# ATSAMRH707F18A device description
Architecture: CORTEX-M7; Family: SAMRH; Series: SAMRH707
Registers are 32-bit, read-write, no defined reset value unless marked. A register's access mark holds for its fields unless they carry their own. Offsets are from the block's base; [hi:lo] are bit positions; {n}, {i} and the like mark numbered series.

## NMIC — Non-maskable Interrupt Controller
Instances: NMIC 0x400A8000
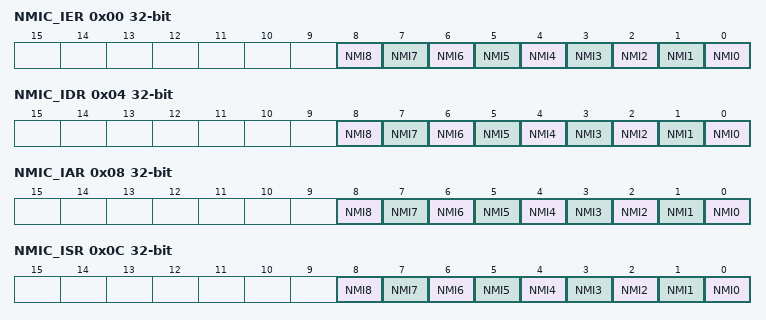
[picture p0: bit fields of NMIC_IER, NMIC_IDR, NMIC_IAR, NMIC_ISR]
0x00 NMIC_IER wo — Interrupt Enable Register
  [n] NMI{n} (n=0..8) — Non-maskable Interrupt {n} Enable
0x04 NMIC_IDR wo — Interrupt Disable Register
  [n] NMI{n} (n=0..8) — Non-maskable Interrupt {n} Disable
0x08 NMIC_IAR ro — Interrupt Active Register
  [n] NMI{n} (n=0..8) — Active Interrupt {n}
0x0C NMIC_ISR ro — Interrupt Status Register
  [n] NMI{n} (n=0..8) — Non-maskable Interrupt Source {n} Pending (cleared on read)
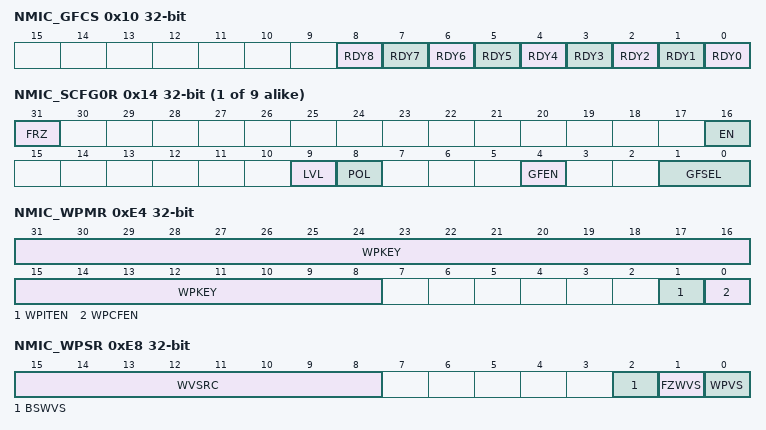
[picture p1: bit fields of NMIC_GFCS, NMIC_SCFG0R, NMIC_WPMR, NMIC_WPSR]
0x10 NMIC_GFCS ro — Glitch Filter Configuration Status Register
  [n] RDY{n} (n=0..8) — Filter {n} Configuration Ready
{0x14+4i} NMIC_SCFG{i}R (i=0..8) — Source Configuration Register {i}
  [31] FRZ — Interrupt Line Freeze
  [16] EN — Source Enable
  [9] LVL — Level Detection (LVL bit is read-only in NMIC_SCFG1 to 8)
  [8] POL — Polarity (POL bit is read-only in NMIC_SCFG1 to 8)
  [4] GFEN — Glitch Filter Enable (GFEN bit is read-only in NMIC_SCFG1 to 8)
  [1:0] GFSEL — Glitch Filter Selector (GFSEL field is read-only in NMIC_SCFG1 to 8)
0xE4 NMIC_WPMR — Write Protection Mode Register
  [31:8] WPKEY — Write Protection Key
    0x4E4D49=PASSWD (Writing any other value in this field aborts the write operation of the WPCFEN and WPITEN bit. Always reads as 0.)
  [1] WPITEN — Write Protection Interrupt Enable
  [0] WPCFEN — Write Protection Configuration Enable
0xE8 NMIC_WPSR ro — Write Protection Status Register
  [15:8] WVSRC — Write Violation Source
  [2] BSWVS — Busy Register Write Violation Status
  [1] FZWVS — Frozen Register Write Violation Status
  [0] WPVS — Write Protection Register Violation Status

## PCC — Parallel Capture Controller
Instances: PCC 0x4001C000
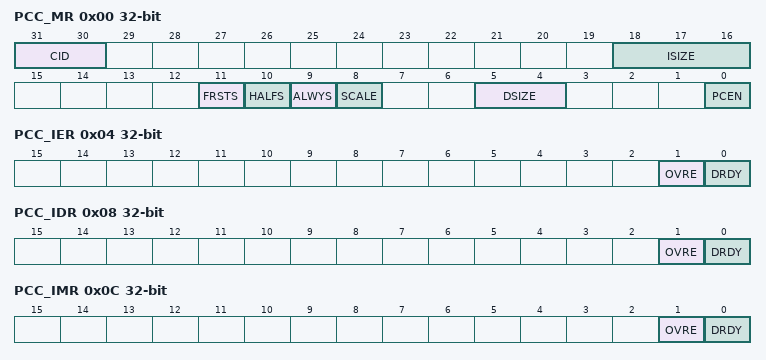
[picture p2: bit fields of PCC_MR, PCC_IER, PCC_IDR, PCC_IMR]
0x00 PCC_MR — Mode Register
  [31:30] CID — Clear If Disabled
    0=NONE (Clear not enabled); 1=DEN1 (Clear on falling edge on DEN1 enabled); 2=DEN2 (Clear on falling edge on DEN2 enabled); 3=EITHER (Clear on falling edge on either DEN1 or DEN2 enabled)
  [18:16] ISIZE — Input Data Size
    0=8_BITS (Input data bus size is 8 bits); 1=10_BITS (Input data bus size is 10 bits); 2=12_BITS (Input data bus size is 12 bits); 3=14_BITS (Input data bus size is 14 bits); 4=16_BITS (Input data bus size is 16 bits)
  [11] FRSTS — First Sample
  [10] HALFS — Half Sampling
  [9] ALWYS — Always Sampling
  [8] SCALE — Scale Data
  [5:4] DSIZE — Data Size
    0=1_DATA (1 data is read in the PCC_RHR); 1=2_DATA (2 data are read in the PCC_RHR); 2=4_DATA (4 data are read in the PCC_RHR (only for 8 bits data size, ISIZE = 0))
  [0] PCEN — Parallele Capture Enable
0x04 PCC_IER wo (atomic set of PCC_IMR) — Interrupt Enable Register
  [1] OVRE — Overrun Error Interrupt Enable
  [0] DRDY — Data Ready Interrupt Enable
0x08 PCC_IDR wo (atomic clear of PCC_IMR) — Interrupt Disable Register
  [1] OVRE — Overrun Error Interrupt Disable
  [0] DRDY — Data Ready Interrupt Disable
0x0C PCC_IMR ro — Interrupt Mask Register
  [1] OVRE — Overrun Error Interrupt Mask
  [0] DRDY — Data Ready Interrupt Mask
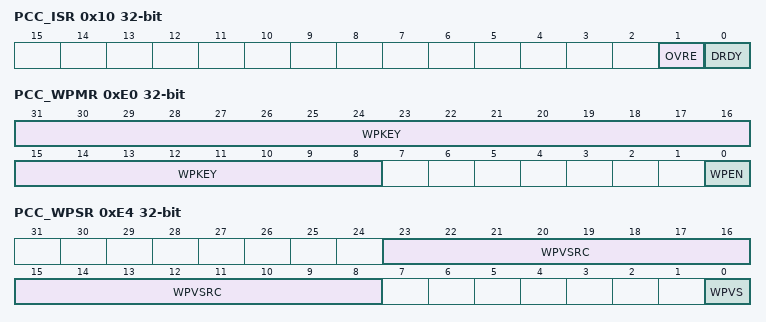
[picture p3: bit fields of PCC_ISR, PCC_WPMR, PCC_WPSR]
0x10 PCC_ISR ro — Interrupt Status Register
  [1] OVRE — Overrun Error.
  [0] DRDY — Data Ready
0x14 PCC_RHR ro — Reception Holding Register
  [31:0] RDATA — Reception Data.
0xE0 PCC_WPMR — Write Protection Mode Register
  [31:8] WPKEY — Write Protection Key.
    0x504343=PASSWD (Writing any other value in this field aborts the write operation of the WPEN bit. Always reads as 0.)
  [0] WPEN — Write Protection Enable
0xE4 PCC_WPSR ro — Write Protection Status Register
  [23:8] WPVSRC — Write Protection Violation Source
  [0] WPVS — Write Protection Violation Status

## RSTC — Reset Controller
Instances: RSTC 0x40100200
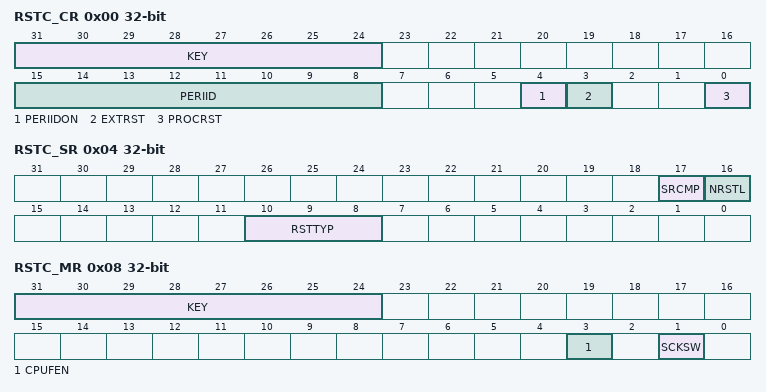
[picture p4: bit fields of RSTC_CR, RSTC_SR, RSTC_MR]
0x00 RSTC_CR wo — Control Register
  [31:24] KEY — System Reset Key
    165=PASSWD (Writing any other value in this field aborts the write operation.)
  [15:8] PERIID — Peripheral Identifier
  [4] PERIIDON — External Reset
  [3] EXTRST — External Reset
  [0] PROCRST — Processor Reset
0x04 RSTC_SR ro — Status Register
  [17] SRCMP — Software Reset Command in Progress
  [16] NRSTL — NRST Pin Level
  [10:8] RSTTYP — Reset Type
    0=GENERAL_RST (First powerup reset); 2=WDT_RST (Watchdog fault occurred); 3=SOFT_RST (Processor reset required by the software); 6=CPU_FAIL_RST (CPU clock failure detection occurred); 7=SLCK_XTAL_RST (32.768 kHz crystal failure detection fault occurred)
0x08 RSTC_MR — Mode Register
  [31:24] KEY — Write Access Password
    165=PASSWD (Writing any other value in this field aborts the write operation. Always reads as 0.)
  [3] CPUFEN — CPU Fail Enable
  [1] SCKSW — Slow Clock Switching
